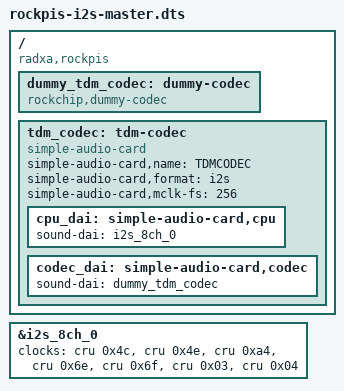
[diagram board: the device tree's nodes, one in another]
/dts-v1/;
/plugin/;

/ {
    compatible = "radxa,rockpis", "rockchip,rk3308";
	
 	fragment@0 {
 		target-path = "/";
 		__overlay__ {
            dummy_tdm_codec: dummy-codec {
                status = "okay";
                compatible = "rockchip,dummy-codec";
                #sound-dai-cells = <0>;
            };
 		};
 	};

    fragment@1 {
        target = <&i2s_8ch_0>;
        __overlay__ {
			#sound-dai-cells = <0>;
			clock-names = "mclk_tx", "mclk_rx", "hclk", "mclk_tx_src", "mclk_rx_src", "mclk_root0", "mclk_root1";
			clocks = <&cru 0x4c>, <&cru 0x4e>, <&cru 0xa4>, <&cru 0x6e>, <&cru 0x6f>, <&cru 0x03>, <&cru 0x04>;
            status = "okay";
        };
    };

    fragment@3 {
        target-path = "/";
        __overlay__ {
			tdm_codec: tdm-codec {
				compatible = "simple-audio-card";
				simple-audio-card,name = "TDMCODEC";
				simple-audio-card,format = "i2s";
				simple-audio-card,mclk-fs = <256>;
				status = "okay";

				cpu_dai: simple-audio-card,cpu {
					sound-dai = <&i2s_8ch_0>;
				};
						
				codec_dai: simple-audio-card,codec {
					sound-dai = <&dummy_tdm_codec>;
				};
			};
		};
    };
};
